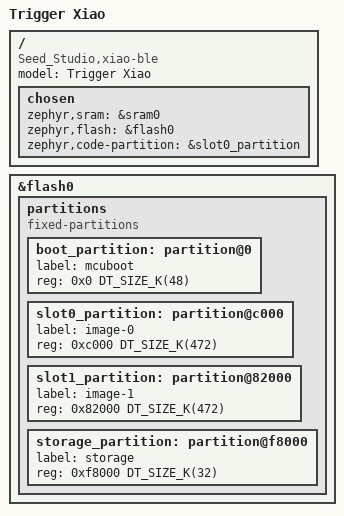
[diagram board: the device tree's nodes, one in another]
/dts-v1/;

#include <nordic/nrf52840_qiaa.dtsi>
#include "xiao_ble-pinctrl.dtsi"

/ {
	model = "Trigger Xiao";
	compatible = "Seed_Studio,xiao-ble";

	chosen {
		zephyr,sram = &sram0;
		zephyr,flash = &flash0;
		zephyr,code-partition = &slot0_partition;
	};
};

&flash0 {
	partitions {
		compatible = "fixed-partitions";
		#address-cells = <1>;
		#size-cells = <1>;

		boot_partition: partition@0 {
			label = "mcuboot";
			reg = <0x0 DT_SIZE_K(48)>;
		};

		slot0_partition: partition@c000 {
			label = "image-0";
			reg = <0xc000 DT_SIZE_K(472)>;
		};

		slot1_partition: partition@82000 {
			label = "image-1";
			reg = <0x82000 DT_SIZE_K(472)>;
		};

		storage_partition: partition@f8000 {
			label = "storage";
			reg = <0xf8000 DT_SIZE_K(32)>;
		};
	};
};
